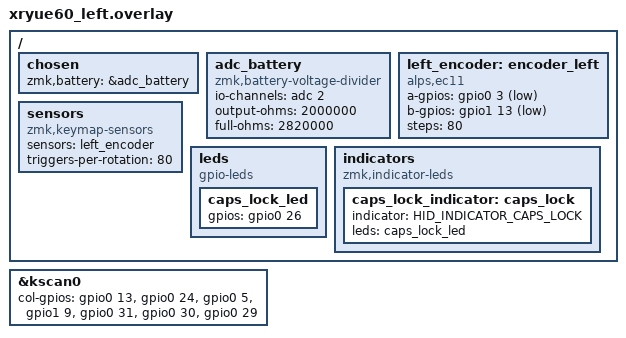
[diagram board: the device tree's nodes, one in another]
/*
 * Copyright (c) 2020 Pete Johanson
 *
 * SPDX-License-Identifier: MIT
 */

#include <dt-bindings/zmk/hid_indicators.h>
#include "xryue60.dtsi"

&kscan0 {
col-gpios
			= <&gpio0 13 GPIO_ACTIVE_HIGH>
			, <&gpio0 24 GPIO_ACTIVE_HIGH>
			, <&gpio0 5 GPIO_ACTIVE_HIGH>
			, <&gpio1 9 GPIO_ACTIVE_HIGH>			
			, <&gpio0 31 GPIO_ACTIVE_HIGH>
			, <&gpio0 30 GPIO_ACTIVE_HIGH>
			, <&gpio0 29 GPIO_ACTIVE_HIGH>
			;
};



/ {
chosen {
zmk,battery = &adc_battery;
};
adc_battery: adc_battery {
    compatible = "zmk,battery-voltage-divider";
    io-channels = <&adc 2>;          // 因为使用了 P0.04 / AIN2
    output-ohms = <2000000>;         // 对应你的 R11 (2MΩ)
    full-ohms = <2820000>;           // 对应你的 R10 + R11 (820kΩ + 2MΩ)
};

  left_encoder: encoder_left {
        compatible = "alps,ec11";
        a-gpios = <&gpio0 3 (GPIO_PULL_UP | GPIO_ACTIVE_LOW)>;
        b-gpios = <&gpio1 13 (GPIO_PULL_UP | GPIO_ACTIVE_LOW)>;
        steps = <80>;
        status = "okay";
    };

sensors: sensors {
        compatible = "zmk,keymap-sensors";
        sensors = <&left_encoder>;
        triggers-per-rotation = <80>;
    };


leds {
        compatible = "gpio-leds";
/*
        num_lock_led: num_lock_led {
            gpios = <&gpio0 1 GPIO_ACTIVE_HIGH>;
        };
 */
        caps_lock_led: caps_lock_led {
            gpios = <&gpio0 26 GPIO_ACTIVE_HIGH>;
        };
    };


	indicators {
        compatible = "zmk,indicator-leds";
          caps_lock_indicator: caps_lock {
            indicator = <HID_INDICATOR_CAPS_LOCK>;
            leds = <&caps_lock_led>;
        };
    };

};
